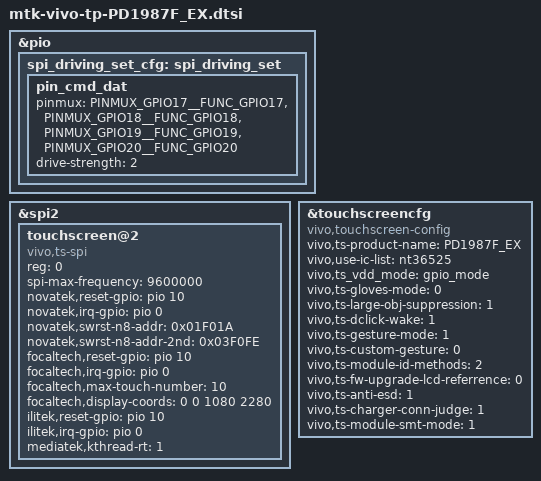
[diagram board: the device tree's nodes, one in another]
&pio {
	spi_driving_set_cfg:spi_driving_set {
		pin_cmd_dat {
			pinmux = <PINMUX_GPIO17__FUNC_GPIO17>,
				 <PINMUX_GPIO18__FUNC_GPIO18>,
				 <PINMUX_GPIO19__FUNC_GPIO19>,
				 <PINMUX_GPIO20__FUNC_GPIO20>;
			drive-strength = <2>;
		};
	};
};
&spi2 {
	#address-cells = <1>;
	#size-cells = <0>;
	touchscreen@2 {
		compatible = "vivo,ts-spi";
		reg = <0>; //Same as CS ID

		spi-max-frequency = <9600000>;	//4800000,9600000,15000000,19200000
		//pinctrl-names ="default";
		//pinctrl-0 = <&ts_reset_active>;
		//novatek dtsi
		novatek,reset-gpio = <&pio 10 0x00>;
		novatek,irq-gpio = <&pio 0 0x02>;
		//novatek,clk-gpio = <&pio 14 0x00>;
		//novatek,cs-gpio = <&pio 16 0x00>;
		novatek,swrst-n8-addr = <0x01F01A>;
		/* 672A, 525B */
		novatek,swrst-n8-addr-2nd = <0x03F0FE>;
		//novatek,spi-rd-fast-addr = <0x03F310>;

		focaltech,reset-gpio = <&pio 10 0x00>;
		focaltech,irq-gpio = <&pio 0 0x02>;
		focaltech,max-touch-number = <10>;
		focaltech,display-coords = <0 0 1080 2280>;

		//ilitek
		ilitek,reset-gpio = <&pio 10 0x00>;
		ilitek,irq-gpio = <&pio 0 0x02>;

		mediatek,kthread-rt = <1>;
	};
};
&touchscreencfg {
	compatible = "vivo,touchscreen-config";
	vivo,ts-product-name="PD1987F_EX";
	vivo,use-ic-list="nt36525";
	vivo,ts_vdd_mode="gpio_mode";

	vivo,ts-gloves-mode=<0>;
	vivo,ts-large-obj-suppression=<1>;
	vivo,ts-dclick-wake=<1>;
	vivo,ts-gesture-mode=<1>;
	vivo,ts-custom-gesture=<0>;
	vivo,ts-module-id-methods=<2>;
	vivo,ts-fw-upgrade-lcd-referrence=<0>;
	vivo,ts-anti-esd=<1>;
	vivo,ts-charger-conn-judge=<1>;
	vivo,ts-module-smt-mode=<1>;
	status = "okay";
};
